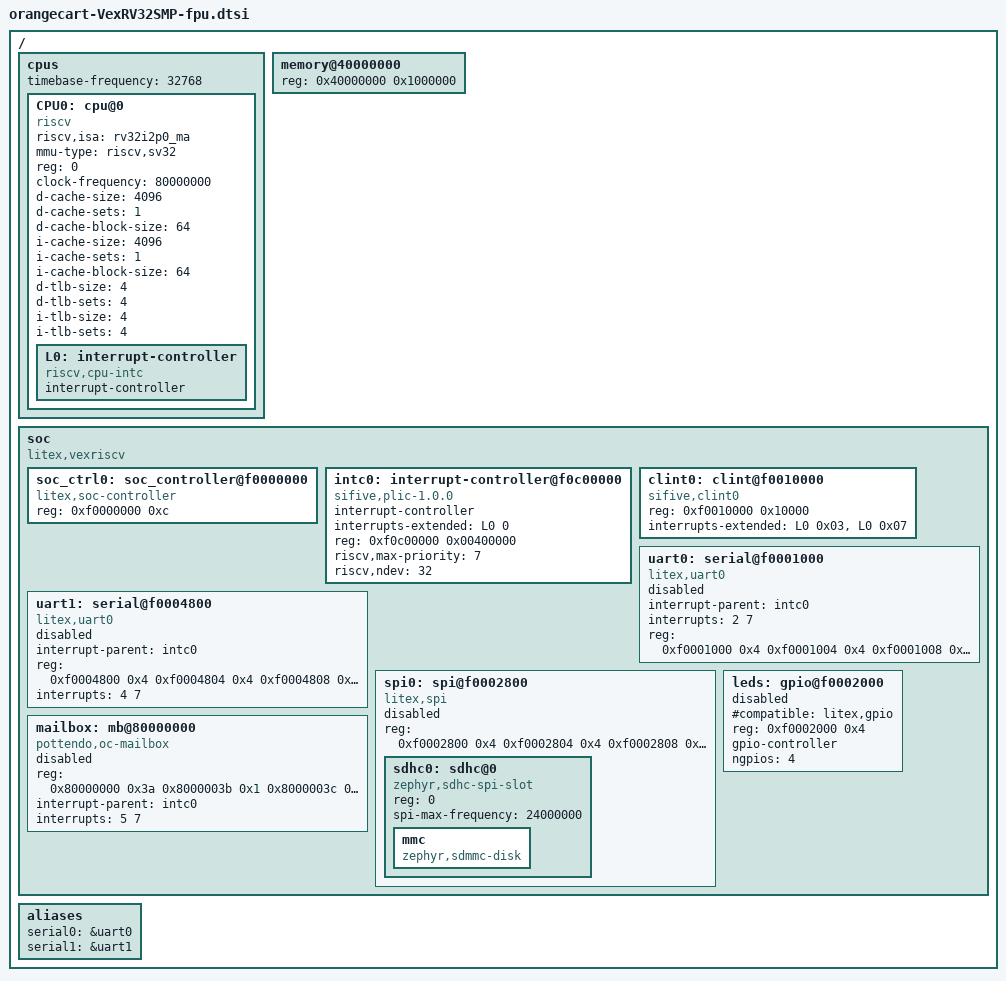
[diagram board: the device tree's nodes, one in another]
/*
 * Copyright (c) 2022 pottendo
 *
 * SPDX-License-Identifier: Apache-2.0
 */

/dts-v1/;

/ {
        #address-cells = <1>;
        #size-cells    = <1>;
        cpus {
            #address-cells = <1>;
            #size-cells    = <0>;
            timebase-frequency = <32768>;

            CPU0: cpu@0 {
                device_type = "cpu";
                compatible = "riscv";
                riscv,isa = "rv32i2p0_ma";
                mmu-type = "riscv,sv32";
                reg = <0>;
                clock-frequency = <80000000>;
                status = "okay";
                
                d-cache-size = <4096>;
                d-cache-sets = <1>;
                d-cache-block-size = <64>;

                i-cache-size = <4096>;
                i-cache-sets = <1>;
                i-cache-block-size = <64>;

                
                d-tlb-size = <4>;
                d-tlb-sets = <4>;

                i-tlb-size = <4>;
                i-tlb-sets = <4>;

                L0: interrupt-controller {
                    #address-cells = <0>;
                    #interrupt-cells = <0x00000001>;
                    interrupt-controller;
                    compatible = "riscv,cpu-intc";
                };
            };
        };
        memory@40000000 {
            device_type = "memory";
            reg = <0x40000000 0x1000000>;
        };
        soc {
            #address-cells = <1>;
            #size-cells    = <1>;
            compatible = "litex,vexriscv";
            //compatible = "simple-bus";
            ranges;

            soc_ctrl0: soc_controller@f0000000 {
                compatible = "litex,soc-controller";
                reg = <0xf0000000 0xc>;
                status = "okay";
            };
/*  older zephyr plic driver
            intc0: interrupt-controller@f0c00000 {
                compatible = "sifive,plic-1.0.0";
                reg = <0xf0c00000 0x00002000
    		        0xf0c02000 0x001fe000
			        0xf0e00000 0x00200000>;
                #address-cells = <0>;
                #interrupt-cells = <2>;
                interrupt-controller;
                reg-names = "prio", "irq_en", "reg";
                //interrupts-extended = <&L0 11>;
                interrupt-parent = <&L0>;
                //interrupts = < 11 >;
                riscv,ndev = <32>;
                riscv,max-priority = <7>;
                status="okay";
            };            

*/
            intc0: interrupt-controller@f0c00000 {
                compatible = "sifive,plic-1.0.0";
                #address-cells = <0>;
                #interrupt-cells = <2>;
                interrupt-controller;
                interrupts-extended = <&L0 0>;
                reg = <0xf0c00000 0x00400000>;
                riscv,max-priority = <7>;
                riscv,ndev = <32>;
                status="okay";
            };

            clint0: clint@f0010000 {
                //interrupt-parent = <&L0>;
                compatible = "sifive,clint0";
                reg = <0xf0010000 0x10000>;
                interrupts-extended = 
                < &L0 0x03 &L0 0x07 >;
                interrupt-names = "soft0", "timer0";
                status="okay";
            };
            uart0: serial@f0001000 {
                compatible = "litex,uart0";
                interrupt-parent = <&intc0>;
                //interrupt-parent = <&L0>;
                interrupts = <2 7>;
                reg = <0xf0001000 0x4
                    0xf0001004 0x4
                    0xf0001008 0x4
                    0xf000100c 0x4
                    0xf0001010 0x4
                    0xf0001014 0x4
                    0xf0001018 0x4
                    0xf000101c 0x4>;
                reg-names =
                    "rxtx",
                    "txfull",
                    "rxempty",
                    "ev_status",
                    "ev_pending",
                    "ev_enable",
                    "txempty",
                    "rxfull";
                status = "disabled";
            };
            uart1: serial@f0004800 {
                compatible = "litex,uart0";
                interrupt-parent = <&intc0>;
                //interrupt-parent = <&L0>;
                reg = <0xf0004800 0x4
                    0xf0004804 0x4
                    0xf0004808 0x4
                    0xf000480c 0x4
                    0xf0004810 0x4
                    0xf0004814 0x4
                    0xf0004818 0x4
                    0xf000481c 0x4>;
                reg-names = "rxtx",
                    "txfull",
                    "rxempty",
                    "ev_status",
                    "ev_pending",
                    "ev_enable",
                    "txempty",
                    "rxfull";
                interrupts = <4 7>;
                status = "disabled";
             };
            
            spi0: spi@f0002800 {
                compatible = "litex,spi";
                reg = <0xf0002800 0x4
                    0xf0002804 0x4
                    0xf0002808 0x4
                    0xf000280c 0x4
                    0xf0002810 0x4
                    0xf0002814 0x4>;
                reg-names = "control",
                    "status",
                    "mosi",
                    "miso",
                    "cs",
                    "loopback";
                status = "disabled";
                #address-cells = <1>;
                #size-cells = <0>;
                sdhc0: sdhc@0 {
                    compatible = "zephyr,sdhc-spi-slot";
                    reg = <0>;
                    status = "okay";
                    mmc {
                        compatible = "zephyr,sdmmc-disk";
                        status = "okay";
                    };
                    spi-max-frequency = <24000000>;
                };
            };
            leds: gpio@f0002000 {
                #compatible = "litex,gpio";
                reg = <0xf0002000 0x4>;
                gpio-controller;
                #gpio-cells = <2>;
                //litex,direction = "out";
                //port-is-output = <true>;
                ngpios = < 4 >;
                status = "disabled";
            };
            mailbox: mb@80000000 {
                compatible = "pottendo,oc-mailbox";
                reg = <0x80000000 0x3a
                       0x8000003b 0x1
                       0x8000003c 0x4>;
                reg-names = "shm", "trigger", "confirm"; 
                interrupt-parent = <&intc0>;
                interrupts = <5 7>;
                status = "disabled";
            };
        };

        aliases {
            serial0 = &uart0;
            serial1 = &uart1;
        };

};

